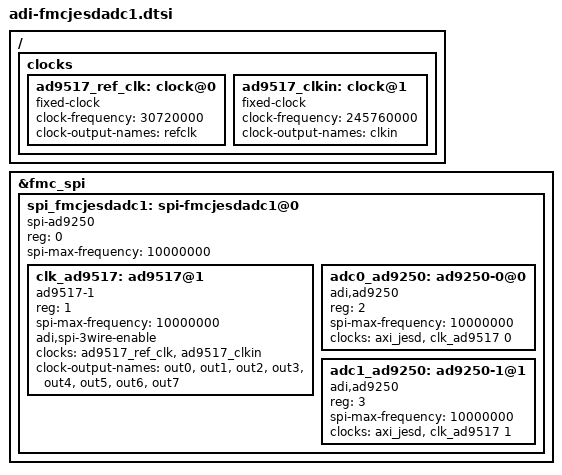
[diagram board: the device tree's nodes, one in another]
/ {
	clocks {
		ad9517_ref_clk: clock@0 {
			#clock-cells = <0>;
			compatible = "fixed-clock";
			clock-frequency = <30720000>;
			clock-output-names = "refclk";
		};
		ad9517_clkin: clock@1 {
			#clock-cells = <0>;
			compatible = "fixed-clock";
			clock-frequency = <245760000>;
			clock-output-names = "clkin";
		};
	};
};

&fmc_spi {
	spi_fmcjesdadc1: spi-fmcjesdadc1@0 {
		#address-cells = <1>;
		#size-cells = <0>;
		compatible = "spi-ad9250";
		reg = <0>;
		spi-max-frequency = <10000000>;

		clk_ad9517: ad9517@1 {
			#clock-cells = <1>;
			compatible = "ad9517-1";
			reg = <1>;
			spi-max-frequency = <10000000>;
			adi,spi-3wire-enable;
			clocks = <&ad9517_ref_clk>, <&ad9517_clkin>;
			clock-names = "refclk", "clkin";
			clock-output-names = "out0", "out1", "out2", "out3", "out4", "out5", "out6", "out7";
		};

		adc0_ad9250: ad9250-0@0 {
			compatible = "adi,ad9250";
			reg = <2>;
			spi-max-frequency = <10000000>;
			clocks = <&axi_jesd>, <&clk_ad9517 0>;
			clock-names = "jesd_dac_clk", "adc_clk";
		};

		adc1_ad9250: ad9250-1@1 {
			compatible = "adi,ad9250";
			reg = <3>;
			spi-max-frequency = <10000000>;
			clocks = <&axi_jesd>, <&clk_ad9517 1>;
			clock-names = "jesd_dac_clk", "adc_clk";
		};
	};
};
